# STM32L486xx register map
File version: 1.0
Registers are 32-bit, access not given, reset 0x0 unless marked. A register's access mark holds for its fields unless they carry their own. Offsets are from the block's base; [hi:lo] are bit positions; {n}, {i} and the like mark numbered series.

## SYSCFG
Base 0x40010000
0x00 MEMRMP
  [n] PAGE{n} (n=0..31), [22] I2C3_FMP, [21] I2C2_FMP, [20] I2C1_FMP, [n+10] I2C_PB{n}_FMP (n=6..9), [4n+2:4n] EXTI{n} (n=0..3), [4n-14:4n-16] EXTI{n} (n=4..7), [4n-30:4n-32] EXTI{n} (n=8..11), [4n-46:4n-48] EXTI{n} (n=12..15), [8] FB_MODE, [8] BOOSTEN, [8] SPF, [3] ECCL, [2] PVDL, [1] SRAM2BSY, [1] SPL, [2:0] MEM_MODE, [0] FWDIS, [0] SRAM2ER, [0] CLL, [7:0] KEY
0x04 CFGR1
0x08 EXTICR.0
0x0C EXTICR.1
0x10 EXTICR.2
0x14 EXTICR.3
0x18 SCSR
0x1C CFGR2
0x20 SWPR
0x24 SKR

## VREFBUF
Base 0x40010030
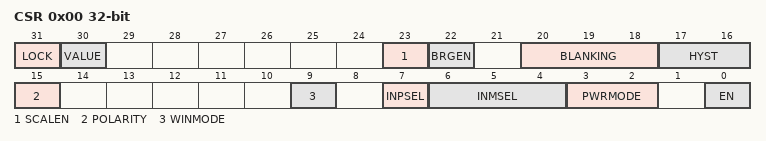
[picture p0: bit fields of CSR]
0x00 CSR
  [3] VRR, [2] VRS, [1] HIZ, [0] ENVR, [5:0] TRIM
0x04 CCR

## COMP1
Base 0x40010200
Same registers: COMP2 0x40010204, COMP12_COMMON 0x40010204
0x00 CSR
  [31] LOCK, [30] VALUE, [23] SCALEN, [22] BRGEN, [20:18] BLANKING, [17:16] HYST, [15] POLARITY, [9] WINMODE, [7] INPSEL, [6:4] INMSEL, [3:2] PWRMODE, [0] EN

## EXTI
Base 0x40010400
0x00 IMR1
  [n] IM{n} (n=0..31), [n] EM{n} (n=0..31), [n] RT{n} (n=18..22), [n] FT{n} (n=18..22), [n] SWI{n} (n=18..22), [n] PIF{n} (n=18..22), [n] RT{n} (n=0..16), [n] FT{n} (n=0..16), [n] SWI{n} (n=0..16), [n] PIF{n} (n=0..16), [n-32] IM{n} (n=32..39), [n-32] EM{n} (n=32..39), [n-32] RT{n} (n=35..38), [n-32] FT{n} (n=35..38), [n-32] SWI{n} (n=35..38), [n-32] PIF{n} (n=35..38)
0x04 EMR1
0x08 RTSR1
0x0C FTSR1
0x10 SWIER1
0x14 PR1
0x20 IMR2
0x24 EMR2
0x28 RTSR2
0x2C FTSR2
0x30 SWIER2
0x34 PR2

## FIREWALL
Base 0x40011C00
0x00 CSSA
0x04 CSL
0x08 NVDSSA
0x0C NVDSL
0x10 VDSSA
0x14 VDSL
0x20 CR

## SDMMC1
Base 0x40012800
0x00 POWER
  [22] SDIOIT, [22] SDIOITC, [22] SDIOITIE, [21] RXDAVL, [21] RXDAVLIE, [20] TXDAVL, [20] TXDAVLIE, [19] RXFIFOE, [19] RXFIFOEIE, [18] TXFIFOE, [18] TXFIFOEIE, [17] RXFIFOF, [17] RXFIFOFIE, [16] TXFIFOF, [16] TXFIFOFIE, [15] RXFIFOHF, [15] RXFIFOHFIE, [14] HWFC_EN, [14] TXFIFOHE, [14] TXFIFOHEIE, [13] NEGEDGE, [13] RXACT, [13] RXACTIE, [12] TXACT, [12] TXACTIE, [12:11] WIDBUS, [11] SDIOSUSPEND, [11] SDIOEN, [11] CMDACT, [11] CMDACTIE, [10] BYPASS, [10] CPSMEN, [10] RWMOD, [10] DBCKEND, [10] DBCKENDC, [10] DBCKENDIE, [9] PWRSAV, [9] WAITPEND, [9] RWSTOP, [9] STBITERR, [9] STBITERRC, [8] CLKEN, [8] WAITINT, [8] RWSTART, [8] DATAEND, [8] DATAENDC, [8] DATAENDIE, [7] CMDSENT, [7] CMDSENTC, [7] CMDSENTIE, [7:6] WAITRESP, [6] CMDREND, [6] CMDRENDC, [6] CMDRENDIE, [5] RXOVERR, [5] RXOVERRC, [5] RXOVERRIE, [7:4] DBLOCKSIZE, [4] TXUNDERR, [4] TXUNDERRC, [4] TXUNDERRIE, [3] DMAEN, [3] DTIMEOUT, [3] DTIMEOUTC, [3] DTIMEOUTIE, [2] DTMODE, [2] CTIMEOUT, [2] CTIMEOUTC, [2] CTIMEOUTIE, [1] DTDIR, [1] DCRCFAIL, [1] DCRCFAILC, [1] DCRCFAILIE, [1:0] PWRCTRL, [7:0] CLKDIV, [31:0] CMDARG, [5:0] CMDINDEX, [5:0] RESPCMD, [31:0] CARDSTATUS{n} (n=1..4), [31:0] DATATIME, [24:0] DATALENGTH, [0] DTEN, [24:0] DATACOUNT, [0] CCRCFAIL, [0] CCRCFAILC, [0] CCRCFAILIE, [23:0] FIFOCOUNT, [31:0] FIFODATA
0x04 CLKCR
0x08 ARG
0x0C CMD
0x10 RESPCMD
{0x10+4i} RESP{i} (i=1..4)
0x24 DTIMER
0x28 DLEN
0x2C DCTRL
0x30 DCOUNT
0x34 STA
0x38 ICR
0x3C MASK
0x48 FIFOCNT
0x80 FIFO

## SAI1
Base 0x40015400
Same registers: SAI2 0x40015800
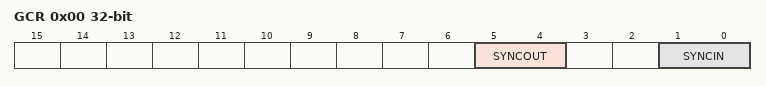
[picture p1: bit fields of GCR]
0x00 GCR
  [5:4] SYNCOUT, [1:0] SYNCIN
0x04 CR1A
0x08 CR2A
0x10 FRCRA
0x1C SLOTRA
0x24 CR1B
0x28 CR2B
0x2C IMRA
0x30 FRCRB
0x3C SLOTRB
0x40 SRA
0x4C IMRB
0x58 CLRFRA
0x60 SRB
0x74 DRA
0x78 CLRFRB
0x94 DRB

## DMA1
Base 0x40020000
Same registers: DMA2 0x40020400
0x00 ISR
  [4n-1] TEIF{n} (n=1..7), [4n-1] CTEIF{n} (n=1..7), [4n-2] HTIF{n} (n=1..7), [4n-2] CHTIF{n} (n=1..7), [4n-3] TCIF{n} (n=1..7), [4n-3] CTCIF{n} (n=1..7), [4n-4] GIF{n} (n=1..7), [4n-4] CGIF{n} (n=1..7), [14] MEM2MEM, [14] MEM2MEM, [14] MEM2MEM, [14] MEM2MEM, [14] MEM2MEM, [14] MEM2MEM, [14] MEM2MEM, [14] MEM2MEM, [14] MEM2MEM, [14] MEM2MEM, [14] MEM2MEM, [14] MEM2MEM, [14] MEM2MEM, [14] MEM2MEM, [13:12] PL, [13:12] PL, [13:12] PL, [13:12] PL, [13:12] PL, [13:12] PL, [13:12] PL, [13:12] PL, [13:12] PL, [13:12] PL, [13:12] PL, [13:12] PL, [13:12] PL, [13:12] PL, [11:10] MSIZE, [11:10] MSIZE, [11:10] MSIZE, [11:10] MSIZE, [11:10] MSIZE, [11:10] MSIZE, [11:10] MSIZE, [11:10] MSIZE, [11:10] MSIZE, [11:10] MSIZE, [11:10] MSIZE, [11:10] MSIZE, [11:10] MSIZE, [11:10] MSIZE, [9:8] PSIZE, [9:8] PSIZE, [9:8] PSIZE, [9:8] PSIZE, [9:8] PSIZE, [9:8] PSIZE, [9:8] PSIZE, [9:8] PSIZE, [9:8] PSIZE, [9:8] PSIZE, [9:8] PSIZE, [9:8] PSIZE, [9:8] PSIZE, [9:8] PSIZE, [7] MINC, [7] MINC, [7] MINC, [7] MINC, [7] MINC, [7] MINC, [7] MINC, [7] MINC, [7] MINC, [7] MINC, [7] MINC, [7] MINC, [7] MINC, [7] MINC, [6] PINC, [6] PINC, [6] PINC, [6] PINC, [6] PINC, [6] PINC, [6] PINC, [6] PINC, [6] PINC, [6] PINC, [6] PINC, [6] PINC, [6] PINC, [6] PINC, [5] CIRC, [5] CIRC, [5] CIRC, [5] CIRC, [5] CIRC, [5] CIRC, [5] CIRC, [5] CIRC, [5] CIRC, [5] CIRC, [5] CIRC, [5] CIRC, [5] CIRC, [5] CIRC, [4] DIR, [4] DIR, [4] DIR, [4] DIR, [4] DIR, [4] DIR, [4] DIR, [4] DIR, [4] DIR, [4] DIR, [4] DIR, [4] DIR, [4] DIR, [4] DIR, [3] TEIE, [3] TEIE, [3] TEIE, [3] TEIE, [3] TEIE, [3] TEIE, [3] TEIE, [3] TEIE, [3] TEIE, [3] TEIE, [3] TEIE, [3] TEIE, [3] TEIE, [3] TEIE, [2] HTIE, [2] HTIE, [2] HTIE, [2] HTIE, [2] HTIE, [2] HTIE, [2] HTIE, [2] HTIE, [2] HTIE, [2] HTIE, [2] HTIE, [2] HTIE, [2] HTIE, [2] HTIE, [1] TCIE, [1] TCIE, [1] TCIE, [1] TCIE, [1] TCIE, [1] TCIE, [1] TCIE, [1] TCIE, [1] TCIE, [1] TCIE, [1] TCIE, [1] TCIE, [1] TCIE, [1] TCIE, [0] EN, [0] EN, [15:0] NDT, [15:0] NDT, [31:0] PA, [31:0] PA, [0] EN, [0] EN, [31:0] MA, [15:0] NDT, [31:0] MA, [15:0] NDT, [31:0] PA, [31:0] PA, [0] EN, [0] EN, [31:0] MA, [15:0] NDT, [31:0] MA, [15:0] NDT, [31:0] PA, [31:0] PA, [0] EN, [0] EN, [31:0] MA, [15:0] NDT, [31:0] MA, [15:0] NDT, [31:0] PA, [31:0] PA, [0] EN, [0] EN, [31:0] MA, [15:0] NDT, [31:0] MA, [15:0] NDT, [31:0] PA, [31:0] PA, [0] EN, [0] EN, [31:0] MA, [15:0] NDT, [31:0] MA, [15:0] NDT, [31:0] PA, [31:0] PA, [0] EN, [0] EN, [31:0] MA, [15:0] NDT, [31:0] MA, [15:0] NDT, [31:0] PA, [31:0] PA, [31:0] MA, [31:0] MA
0x04 IFCR
0x08 CCR1
0x0C CNDTR1
{0x0+0x14*i} CPAR{i} (i=1..7)
0x1C CCR2
{0xC+0x14*i} CMAR{i} (i=1..7)
0x20 CNDTR2
0x30 CCR3
0x34 CNDTR3
0x44 CCR4
0x48 CNDTR4
0x58 CCR5
0x5C CNDTR5
0x6C CCR6
0x70 CNDTR6
0x80 CCR7
0x84 CNDTR7
